# 602 register map
Vendor: bouffalolab; Series: WiFi BT
CPU: 602, little endian
Registers are 32-bit, read-write, reset 0x0 unless marked. A register's access mark holds for its fields unless they carry their own. Offsets are from the block's base; [hi:lo] are bit positions; {n}, {i} and the like mark numbered series.

## pwm
Base 0x4000A400
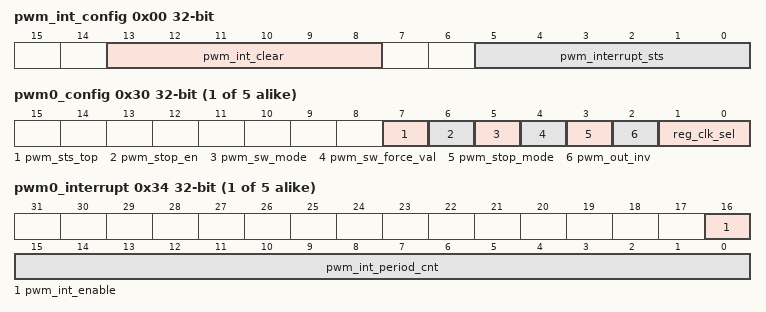
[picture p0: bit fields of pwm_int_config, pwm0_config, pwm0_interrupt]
0x00 pwm_int_config
  [13:8] pwm_int_clear, [5:0] pwm_interrupt_sts
{0x20+0x20*i} pwm{i}_clkdiv (i=0..4)
  [15:0] pwm_clk_div
{0x24+0x20*i} pwm{i}_thre1 (i=0..4)
  [15:0] pwm_thre1
{0x28+0x20*i} pwm{i}_thre2 (i=0..4)
  [15:0] pwm_thre2
{0x2C+0x20*i} pwm{i}_period (i=0..4)
  [15:0] pwm_period
{0x30+0x20*i} pwm{i}_config (i=0..4)
  [7] pwm_sts_top, [6] pwm_stop_en, [5] pwm_sw_mode, [4] pwm_sw_force_val, [3] pwm_stop_mode, [2] pwm_out_inv, [1:0] reg_clk_sel
{0x34+0x20*i} pwm{i}_interrupt (i=0..4)
  [16] pwm_int_enable, [15:0] pwm_int_period_cnt

## timer
Base 0x4000A500
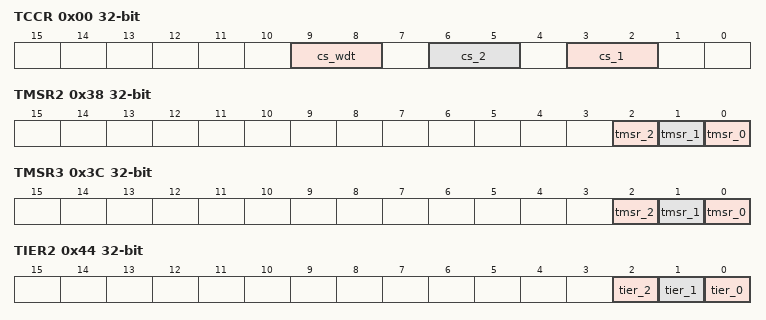
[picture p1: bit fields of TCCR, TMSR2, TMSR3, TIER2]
0x00 TCCR
  [9:8] cs_wdt, [6:5] cs_2, [3:2] cs_1
{0x10+4i} TMR2_{i} (i=0..2)
  [31:0] tmr
{0x1C+4i} TMR3_{i} (i=0..2)
  [31:0] tmr
0x2C TCR2
  [31:0] tcr
0x30 TCR3
  [31:0] tcr3_counter
0x38 TMSR2
  [2] tmsr_2, [1] tmsr_1, [0] tmsr_0
0x3C TMSR3
  [2] tmsr_2, [1] tmsr_1, [0] tmsr_0
0x44 TIER2
  [2] tier_2, [1] tier_1, [0] tier_0
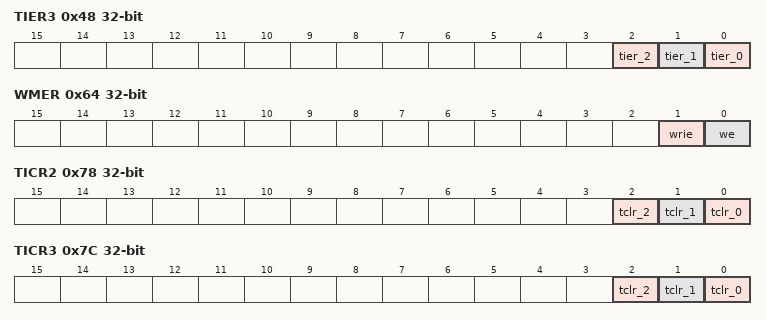
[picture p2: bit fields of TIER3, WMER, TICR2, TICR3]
0x48 TIER3
  [2] tier_2, [1] tier_1, [0] tier_0
0x50 TPLVR2
  [31:0] tplvr
0x54 TPLVR3
  [31:0] tplvr
0x5C TPLCR2
  [1:0] tplcr
0x60 TPLCR3
  [1:0] tplcr
0x64 WMER
  [1] wrie, [0] we
0x68 WMR
  [15:0] wmr
0x6C WVR
  [15:0] wvr
0x70 WSR
  [0] wts
0x78 TICR2
  [2] tclr_2, [1] tclr_1, [0] tclr_0
0x7C TICR3
  [2] tclr_2, [1] tclr_1, [0] tclr_0
0x80 WICR
  [0] wiclr
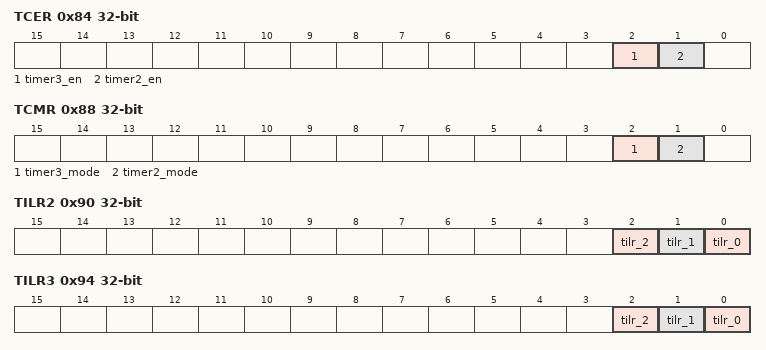
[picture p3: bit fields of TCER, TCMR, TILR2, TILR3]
0x84 TCER
  [2] timer3_en, [1] timer2_en
0x88 TCMR
  [2] timer3_mode, [1] timer2_mode
0x90 TILR2
  [2] tilr_2, [1] tilr_1, [0] tilr_0
0x94 TILR3
  [2] tilr_2, [1] tilr_1, [0] tilr_0
0x98 WCR
  [0] wcr
0x9C WFAR
  [15:0] wfar
0xA0 WSAR
  [15:0] wsar
0xA8 TCVWR2
  [31:0] tcvwr
0xAC TCVWR3
  [31:0] tcvwr
0xB4 TCVSYN2
0xB8 TCVSYN3
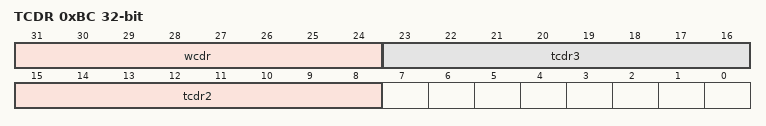
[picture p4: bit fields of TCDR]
0xBC TCDR
  [31:24] wcdr, [23:16] tcdr3, [15:8] tcdr2

## ir
Base 0x4000A600
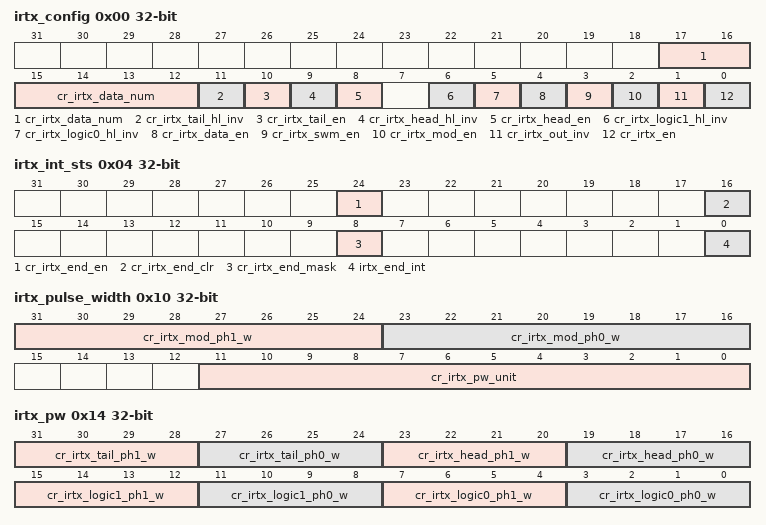
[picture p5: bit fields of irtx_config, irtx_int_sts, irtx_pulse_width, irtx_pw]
0x00 irtx_config
  [17:12] cr_irtx_data_num, [11] cr_irtx_tail_hl_inv, [10] cr_irtx_tail_en, [9] cr_irtx_head_hl_inv, [8] cr_irtx_head_en, [6] cr_irtx_logic1_hl_inv, [5] cr_irtx_logic0_hl_inv, [4] cr_irtx_data_en, [3] cr_irtx_swm_en, [2] cr_irtx_mod_en, [1] cr_irtx_out_inv, [0] cr_irtx_en
0x04 irtx_int_sts
  [24] cr_irtx_end_en, [16] cr_irtx_end_clr, [8] cr_irtx_end_mask, [0] irtx_end_int
0x08 irtx_data_word0
  [31:0] cr_irtx_data_word0
0x0C irtx_data_word1
  [31:0] cr_irtx_data_word1
0x10 irtx_pulse_width
  [31:24] cr_irtx_mod_ph1_w, [23:16] cr_irtx_mod_ph0_w, [11:0] cr_irtx_pw_unit
0x14 irtx_pw
  [31:28] cr_irtx_tail_ph1_w, [27:24] cr_irtx_tail_ph0_w, [23:20] cr_irtx_head_ph1_w, [19:16] cr_irtx_head_ph0_w, [15:12] cr_irtx_logic1_ph1_w, [11:8] cr_irtx_logic1_ph0_w, [7:4] cr_irtx_logic0_ph1_w, [3:0] cr_irtx_logic0_ph0_w
{0x40+4i} irtx_swm_pw_{i} (i=0..7)
  [31:0] cr_irtx_swm_pw_{i}
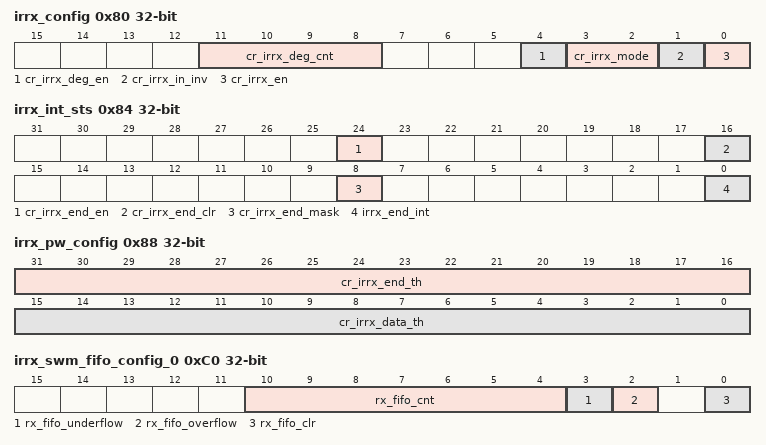
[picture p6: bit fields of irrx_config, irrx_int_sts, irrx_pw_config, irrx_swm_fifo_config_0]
0x80 irrx_config
  [11:8] cr_irrx_deg_cnt, [4] cr_irrx_deg_en, [3:2] cr_irrx_mode, [1] cr_irrx_in_inv, [0] cr_irrx_en
0x84 irrx_int_sts
  [24] cr_irrx_end_en, [16] cr_irrx_end_clr, [8] cr_irrx_end_mask, [0] irrx_end_int
0x88 irrx_pw_config
  [31:16] cr_irrx_end_th, [15:0] cr_irrx_data_th
0x90 irrx_data_count
  [6:0] sts_irrx_data_cnt
0x94 irrx_data_word0
  [31:0] sts_irrx_data_word0
0x98 irrx_data_word1
  [31:0] sts_irrx_data_word1
0xC0 irrx_swm_fifo_config_0
  [10:4] rx_fifo_cnt, [3] rx_fifo_underflow, [2] rx_fifo_overflow, [0] rx_fifo_clr
0xC4 irrx_swm_fifo_rdata
  [15:0] rx_fifo_rdata

## cks
Base 0x4000A000
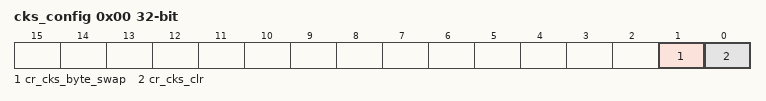
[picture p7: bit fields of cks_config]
0x00 cks_config
  [1] cr_cks_byte_swap, [0] cr_cks_clr
0x04 data_in
  [7:0] data_in
0x08 cks_out
  [15:0] cks_out

## dma
Base 0x4000C000
0x00 DMA_IntStatus
  [7:0] IntStatus
0x04 DMA_IntTCStatus
  [7:0] IntTCStatus
0x08 DMA_IntTCClear
  [7:0] IntTCClear
0x0C DMA_IntErrorStatus
  [7:0] IntErrorStatus
0x10 DMA_IntErrClr
  [7:0] IntErrClr
0x14 DMA_RawIntTCStatus
  [7:0] RawIntTCStatus
0x18 DMA_RawIntErrorStatus
  [7:0] RawIntErrorStatus
0x1C DMA_EnbldChns
  [7:0] EnabledChannels
0x20 DMA_SoftBReq
0x24 DMA_SoftSReq
0x28 DMA_SoftLBReq
0x2C DMA_SoftLSReq
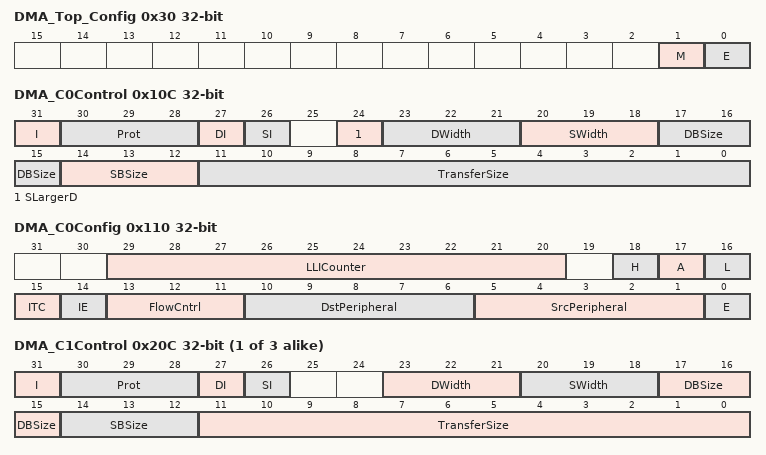
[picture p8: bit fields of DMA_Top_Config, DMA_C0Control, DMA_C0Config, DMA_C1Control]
0x30 DMA_Top_Config
  [1] M, [0] E
0x34 DMA_Sync
{0x100+0x100*i} DMA_C{i}SrcAddr (i=0..3)
  [31:0] SrcAddr
{0x104+0x100*i} DMA_C{i}DstAddr (i=0..3)
  [31:0] DstAddr
0x108 DMA_C0LLI
  [31:0] LLI
0x10C DMA_C0Control
  [31] I, [30:28] Prot, [27] DI, [26] SI, [24] SLargerD, [23:21] DWidth, [20:18] SWidth, [17:15] DBSize, [14:12] SBSize, [11:0] TransferSize
0x110 DMA_C0Config
  [29:20] LLICounter, [18] H, [17] A, [16] L, [15] ITC, [14] IE, [13:11] FlowCntrl, [10:6] DstPeripheral, [5:1] SrcPeripheral, [0] E
{0x108+0x100*i} DMA_C{i}LLI (i=1..3)
  [31:2] LLI
{0x10C+0x100*i} DMA_C{i}Control (i=1..3)
  [31] I, [30:28] Prot, [27] DI, [26] SI, [23:21] DWidth, [20:18] SWidth, [17:15] DBSize, [14:12] SBSize, [11:0] TransferSize
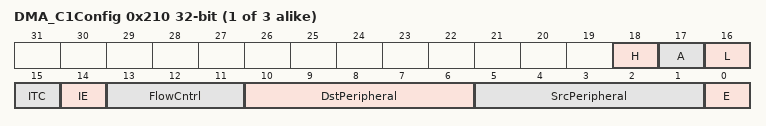
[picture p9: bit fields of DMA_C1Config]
{0x110+0x100*i} DMA_C{i}Config (i=1..3)
  [18] H, [17] A, [16] L, [15] ITC, [14] IE, [13:11] FlowCntrl, [10:6] DstPeripheral, [5:1] SrcPeripheral, [0] E
